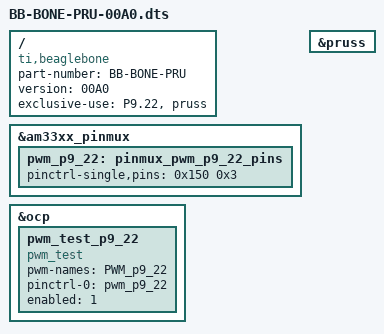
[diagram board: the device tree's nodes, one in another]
/dts-v1/;
/plugin/;

/ {
	compatible = "ti,beaglebone", "ti,beaglebone-black";

	/* identification */
	part-number = "BB-BONE-PRU";
	version = "00A0";

	/* state the resources this cape uses or prepare to get winged! */
   	 exclusive-use =
        	/* the pin header P8 uses */
        	"P9.22", /* mode 3     */
        	/* Hardware IP cores in use */
        	"pruss"; 


	fragment@0 {
		target = <&am33xx_pinmux>;
		__overlay__ {
			pwm_p9_22: pinmux_pwm_p9_22_pins {
				pinctrl-single,pins = <0x150 0x3>;
			};
		};
	};

	fragment@1 {
		target = <&ocp>;
		__overlay__ {
			pwm_test_p9_22 {
				compatible	= "pwm_test";
				pwm-names 	= "PWM_p9_22";
				pinctrl-names	= "default";
				pinctrl-0	= <&pwm_p9_22>;
				enabled		= <1>;
				status 		= "okay";
			};
		};
	};

 	fragment@2 {
  		   target = <&pruss>;
		   __overlay__ {
		   	       status = "okay";

    	           };
        };

};
